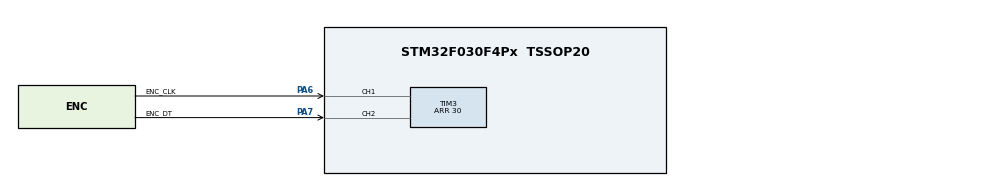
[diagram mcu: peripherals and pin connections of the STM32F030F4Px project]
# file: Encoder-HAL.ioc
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Mcu.Family=STM32F0
Mcu.Name=STM32F030F4Px
Mcu.Package=TSSOP20
NVIC.TIM3_IRQn=true\:0\:0\:false\:false\:true\:true\:true
PA13.Mode=Serial_Wire
PA13.Signal=SYS_SWDIO
PA14.Mode=Serial_Wire
PA14.Signal=SYS_SWCLK
PA6.GPIO_Label=ENC_CLK
PA6.Signal=S_TIM3_CH1
PA7.GPIO_Label=ENC_DT
PA7.Signal=S_TIM3_CH2
ProjectManager.HeapSize=0x200
ProjectManager.StackSize=0x400
ProjectManager.TargetToolchain=STM32CubeIDE
SH.S_TIM3_CH1.0=TIM3_CH1,Encoder_Interface
SH.S_TIM3_CH2.0=TIM3_CH2,Encoder_Interface
TIM3.IC1Filter=6
TIM3.IC2Filter=6
TIM3.Period=30
TIM3.TIM_MasterOutputTrigger=TIM_TRGO_RESET
board=custom

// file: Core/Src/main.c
/* USER CODE BEGIN Header */
/**
  ******************************************************************************
  * @file           : main.c
  * @brief          : Main program body
  ******************************************************************************
  * @attention
  *
  * <h2><center>&copy; Copyright (c) 2020 STMicroelectronics.
  * All rights reserved.</center></h2>
  *
  * This software component is licensed by ST under BSD 3-Clause license,
  * the "License"; You may not use this file except in compliance with the
  * License. You may obtain a copy of the License at:
  *                        opensource.org/licenses/BSD-3-Clause
  *
  ******************************************************************************
  */
/* USER CODE END Header */
#include "main.h"

TIM_HandleTypeDef htim3;

/* USER CODE BEGIN PV */

/* Encoder variables */
uint8_t Enc_Counter = 0;

/* USER CODE END PV */

void SystemClock_Config(void);
static void MX_GPIO_Init(void);
static void MX_TIM3_Init(void);

int main(void)
{

  /* MCU Configuration--------------------------------------------------------*/

  /* Reset of all peripherals, Initializes the Flash interface and the Systick. */
  HAL_Init();

  /* Configure the system clock */
  SystemClock_Config();

  /* Initialize all configured peripherals */
  MX_GPIO_Init();
  MX_TIM3_Init();
  /* USER CODE BEGIN 2 */

  /* Rotary (Incremental) encoder */
  HAL_TIM_Encoder_Start(&htim3, TIM_CHANNEL_ALL);

  /* USER CODE END 2 */

  /* Infinite loop */
  /* USER CODE BEGIN WHILE */
  while (1)
  {

	  Enc_Counter = TIM3->CNT;

    /* USER CODE END WHILE */

  }
}

void SystemClock_Config(void)
{
  RCC_OscInitTypeDef RCC_OscInitStruct = {0};
  RCC_ClkInitTypeDef RCC_ClkInitStruct = {0};

  /** Initializes the RCC Oscillators according to the specified parameters
  * in the RCC_OscInitTypeDef structure.
  */
  RCC_OscInitStruct.OscillatorType = RCC_OSCILLATORTYPE_HSI;
  RCC_OscInitStruct.HSIState = RCC_HSI_ON;
  RCC_OscInitStruct.HSICalibrationValue = RCC_HSICALIBRATION_DEFAULT;
  RCC_OscInitStruct.PLL.PLLState = RCC_PLL_NONE;
  if (HAL_RCC_OscConfig(&RCC_OscInitStruct) != HAL_OK)
  {
    Error_Handler();
  }
  /** Initializes the CPU, AHB and APB buses clocks
  */
  RCC_ClkInitStruct.ClockType = RCC_CLOCKTYPE_HCLK|RCC_CLOCKTYPE_SYSCLK
                              |RCC_CLOCKTYPE_PCLK1;
  RCC_ClkInitStruct.SYSCLKSource = RCC_SYSCLKSOURCE_HSI;
  RCC_ClkInitStruct.AHBCLKDivider = RCC_SYSCLK_DIV1;
  RCC_ClkInitStruct.APB1CLKDivider = RCC_HCLK_DIV1;

  if (HAL_RCC_ClockConfig(&RCC_ClkInitStruct, FLASH_LATENCY_0) != HAL_OK)
  {
    Error_Handler();
  }
}

static void MX_TIM3_Init(void)
{

  TIM_Encoder_InitTypeDef sConfig = {0};
  TIM_MasterConfigTypeDef sMasterConfig = {0};

  htim3.Instance = TIM3;
  htim3.Init.Prescaler = 0;
  htim3.Init.CounterMode = TIM_COUNTERMODE_UP;
  htim3.Init.Period = 30;
  htim3.Init.ClockDivision = TIM_CLOCKDIVISION_DIV1;
  htim3.Init.AutoReloadPreload = TIM_AUTORELOAD_PRELOAD_DISABLE;
  sConfig.EncoderMode = TIM_ENCODERMODE_TI1;
  sConfig.IC1Polarity = TIM_ICPOLARITY_RISING;
  sConfig.IC1Selection = TIM_ICSELECTION_DIRECTTI;
  sConfig.IC1Prescaler = TIM_ICPSC_DIV1;
  sConfig.IC1Filter = 6;
  sConfig.IC2Polarity = TIM_ICPOLARITY_RISING;
  sConfig.IC2Selection = TIM_ICSELECTION_DIRECTTI;
  sConfig.IC2Prescaler = TIM_ICPSC_DIV1;
  sConfig.IC2Filter = 6;
  if (HAL_TIM_Encoder_Init(&htim3, &sConfig) != HAL_OK)
  {
    Error_Handler();
  }
  sMasterConfig.MasterOutputTrigger = TIM_TRGO_RESET;
  sMasterConfig.MasterSlaveMode = TIM_MASTERSLAVEMODE_DISABLE;
  if (HAL_TIMEx_MasterConfigSynchronization(&htim3, &sMasterConfig) != HAL_OK)
  {
    Error_Handler();
  }

}

static void MX_GPIO_Init(void)
{

  /* GPIO Ports Clock Enable */
  __HAL_RCC_GPIOA_CLK_ENABLE();

}

void Error_Handler(void)
{
}

/************************ (C) COPYRIGHT STMicroelectronics *****END OF FILE****/
